# PIC32CM6408PL10028 device description
Architecture: CORTEX-M0PLUS; Family: PIC32CMPL; Series: PIC32CMPL10
Registers are 32-bit, read-write, reset 0x0 unless marked. A register's access mark holds for its fields unless they carry their own. Offsets are from the block's base; [hi:lo] are bit positions; {n}, {i} and the like mark numbered series; 'fields as' and 'values as' point back to an identical list; <NAME> marks a mode.

## RTC — Real-Time Counter
Instances: RTC 0x40002400
Modes: MODE0 when RTC.MODE0.CTRLA.MODE=0 (32-bit Counter Mode); MODE1 when RTC.MODE1.CTRLA.MODE=1 (16-bit Counter Mode); MODE2 when RTC.MODE2.CTRLA.MODE=2 (Clock and Calendar Mode with Alarm)
0x0E DBGCTRL 8-bit — Debug Control
  [0] DBGRUN — Debug Run
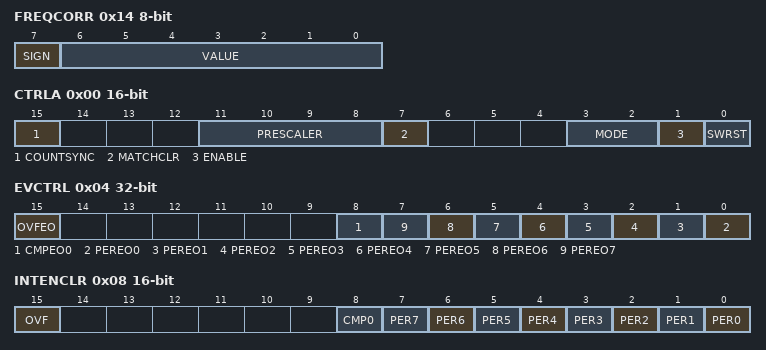
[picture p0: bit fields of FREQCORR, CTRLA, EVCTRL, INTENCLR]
0x14 FREQCORR 8-bit (WSYNC) — Frequency Correction
  [7] SIGN — Correction Sign
  [6:0] VALUE — Correction Value
0x00 CTRLA <MODE0> 16-bit (WSYNC) — MODE0 Control A
  [15] COUNTSYNC — COUNT Read Resynchronization Enable
  [11:8] PRESCALER
    0=OFF (CLK_RTC_CNT = GCLK_RTC/1); 1=DIV1 (CLK_RTC_CNT = GCLK_RTC/1); 2=DIV2 (CLK_RTC_CNT = GCLK_RTC/2); 3=DIV4 (CLK_RTC_CNT = GCLK_RTC/4); 4=DIV8 (CLK_RTC_CNT = GCLK_RTC/8); 5=DIV16 (CLK_RTC_CNT = GCLK_RTC/16); 6=DIV32 (CLK_RTC_CNT = GCLK_RTC/32); 7=DIV64 (CLK_RTC_CNT = GCLK_RTC/64); 8=DIV128 (CLK_RTC_CNT = GCLK_RTC/128); 9=DIV256 (CLK_RTC_CNT = GCLK_RTC/256); 10=DIV512 (CLK_RTC_CNT = GCLK_RTC/512); 11=DIV1024 (CLK_RTC_CNT = GCLK_RTC/1024)
  [7] MATCHCLR — Clear on Match
  [3:2] MODE — Operating Mode
    0=COUNT32 (Mode 0: 32-bit counter); 1=COUNT16 (Mode 1: 16-bit counter); 2=CLOCK (Mode 2: Clock/calendar)
  [1] ENABLE
  [0] SWRST — Software Reset
0x04 EVCTRL <MODE0> — MODE0 Event Control
  [15] OVFEO — Overflow Event Output Enable
  [8] CMPEO0 — Compare 0 Event Output Enable
  [n] PEREO{n} (n=0..7) — Periodic Interval {n} Event Output Enable
0x08 INTENCLR <MODE0> 16-bit (atomic clear) — MODE0 Interrupt Enable Clear
  [15] OVF — Overflow Interrupt Enable
  [8] CMP0 — Compare 0 Interrupt Enable
  [n] PER{n} (n=0..7) — Periodic Interval {n} Interrupt Enable
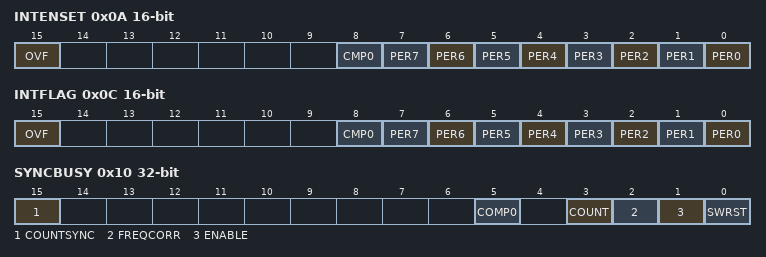
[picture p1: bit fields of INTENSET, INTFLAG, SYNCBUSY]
0x0A INTENSET <MODE0> 16-bit (atomic set) — MODE0 Interrupt Enable Set
  fields as INTENCLR<MODE0>
0x0C INTFLAG <MODE0> 16-bit (atomic clear) — MODE0 Interrupt Flag Status and Clear
  [15] OVF — Overflow
  [8] CMP0 — Compare 0
  [n] PER{n} (n=0..7) — Periodic Interval {n}
0x10 SYNCBUSY <MODE0> ro — MODE0 Synchronization Busy
  [15] COUNTSYNC — COUNT Read Resynchronization Enable Synchronization Busy
  [5] COMP0 — Compare 0 Value Synchronization Busy
  [3] COUNT — Counter Value Synchronization Busy
  [2] FREQCORR — Frequency Correction Synchronization Busy
  [1] ENABLE — Enable Synchronization Busy
  [0] SWRST — Software Reset Synchronization Busy
0x18 COUNT <MODE0> (WSYNC) — MODE0 Counter Value
  [31:0] COUNT — Counter Value
0x20 COMP <MODE0> (WSYNC) — MODE0 Compare # Value
  [31:0] COMP — Compare Value
0x00 CTRLA <MODE1> 16-bit (WSYNC) — MODE1 Control A
  [15] COUNTSYNC — COUNT Read Resynchronization Enable
  [11:8] PRESCALER
    values as CTRLA<MODE0>.PRESCALER
  [3:2] MODE — Operating Mode
    values as CTRLA<MODE0>.MODE
  [1] ENABLE
  [0] SWRST — Software Reset
0x04 EVCTRL <MODE1> — MODE1 Event Control
  [15] OVFEO — Overflow Event Output Enable
  [9] CMPEO1 — Compare 1 Event Output Enable
  [8] CMPEO0 — Compare 0 Event Output Enable
  [n] PEREO{n} (n=0..7) — Periodic Interval {n} Event Output Enable
0x08 INTENCLR <MODE1> 16-bit (atomic clear) — MODE1 Interrupt Enable Clear
  [15] OVF — Overflow Interrupt Enable
  [9] CMP1 — Compare 1 Interrupt Enable
  [8] CMP0 — Compare 0 Interrupt Enable
  [n] PER{n} (n=0..7) — Periodic Interval {n} Interrupt Enable
0x0A INTENSET <MODE1> 16-bit (atomic set) — MODE1 Interrupt Enable Set
  fields as INTENCLR<MODE1>
0x0C INTFLAG <MODE1> 16-bit (atomic clear) — MODE1 Interrupt Flag Status and Clear
  [15] OVF — Overflow
  [9] CMP1 — Compare 1
  [8] CMP0 — Compare 0
  [n] PER{n} (n=0..7) — Periodic Interval {n}
0x10 SYNCBUSY <MODE1> ro — MODE1 Synchronization Busy
  [15] COUNTSYNC — COUNT Read Resynchronization Enable Synchronization Busy
  [6] COMP1 — Compare 1 Value Synchronization Busy
  [5] COMP0 — Compare 0 Value Synchronization Busy
  [4] PER — Counter Period Synchronization Busy
  [3] COUNT — Counter Value Synchronization Busy
  [2] FREQCORR — Frequency Correction Synchronization Busy
  [1] ENABLE — Enable Synchronization Busy
  [0] SWRST — Software Reset Synchronization Busy
0x18 COUNT <MODE1> 16-bit (WSYNC) — MODE1 Counter Value
  [15:0] COUNT — Counter Value
0x1C PER <MODE1> 16-bit (WSYNC) — MODE1 Counter Period
  [15:0] PER — Counter Period
{0x20+2i} COMP[{i}] (i=0..1) <MODE1> 16-bit (WSYNC) — MODE1 Compare # Value
  [15:0] COMP — Compare Value
0x00 CTRLA <MODE2> 16-bit (WSYNC) — MODE2 Control A
  [15] CLOCKSYNC — CLOCK Read Resynchronization Enable
  [11:8] PRESCALER
    values as CTRLA<MODE0>.PRESCALER
  [7] MATCHCLR — Clear on Match
  [6] CLKREP — Clock Representation
    0=CLK24H (24 hour clock format); 1=CLK12H (12 hour (AM/PM) clock format)
  [3:2] MODE — Operating Mode
    values as CTRLA<MODE0>.MODE
  [1] ENABLE
  [0] SWRST — Software Reset
0x04 EVCTRL <MODE2> — MODE2 Event Control
  [15] OVFEO — Overflow Event Output Enable
  [8] ALARMEO0 — Alarm 0 Event Output Enable
  [n] PEREO{n} (n=0..7) — Periodic Interval {n} Event Output Enable
0x08 INTENCLR <MODE2> 16-bit (atomic clear) — MODE2 Interrupt Enable Clear
  [15] OVF — Overflow Interrupt Enable
  [8] ALARM0 — Alarm 0 Interrupt Enable
  [n] PER{n} (n=0..7) — Periodic Interval {n} Interrupt Enable
0x0A INTENSET <MODE2> 16-bit (atomic set) — MODE2 Interrupt Enable Set
  fields as INTENCLR<MODE2>
0x0C INTFLAG <MODE2> 16-bit (atomic clear) — MODE2 Interrupt Flag Status and Clear
  [15] OVF — Overflow
  [8] ALARM0
  [n] PER{n} (n=0..7) — Periodic Interval {n}
0x10 SYNCBUSY <MODE2> ro — MODE2 Synchronization Busy
  [15] CLOCKSYNC — CLOCK Read Resynchronization Enable Synchronization Busy
  [11] MASK0 — Alarm 0 Mask Synchronization Busy
  [5] ALARM0 — Alarm 0 Value Synchronization Busy
  [3] CLOCK — Clock Value Synchronization Busy
  [2] FREQCORR — Frequency Correction Synchronization Busy
  [1] ENABLE — Enable Synchronization Busy
  [0] SWRST — Software Reset Synchronization Busy
0x18 CLOCK <MODE2> (WSYNC) (modes: CLK12H when RTC.CTRLA.CLKREP=1; CLK24H when RTC.CTRLA.CLKREP=0) — MODE2 Clock Value
  [16] INDICATOR <CLK12H> — Meridiem Indicator
    0=AM (Before midday (AM)); 1=PM (After midday (PM))
  [15:12] HOUR <CLK12H>
  [16:12] HOUR <CLK24H>
  [31:26] YEAR <DEFAULT>
  [25:22] MONTH <DEFAULT>
    1=JAN (January); 2=FEB (February); 3=MAR (March); 4=APR (April); 5=MAY; 6=JUN (June); 7=JUL (July); 8=AUG (August); 9=SEP (September); 10=OCT (October); 11=NOV (November); 12=DEC (December)
  [21:17] DAY <DEFAULT>
  [11:6] MINUTE <DEFAULT>
  [5:0] SECOND <DEFAULT>
0x20 ALARM0 <MODE2> (WSYNC) (modes: CLK12H when RTC.CTRLA.CLKREP=1; CLK24H when RTC.CTRLA.CLKREP=0) — MODE2 Alarm 0 Value
  fields as CLOCK<MODE2>
0x24 MASK0 <MODE2> 8-bit (WSYNC) — MODE2 Alarm 0 Mask
  [2:0] SEL — Alarm Mask Selection
    0=OFF (Alarm Disabled); 1=SS (Match seconds only); 2=MMSS (Match seconds and minutes only); 3=HHMMSS (Match seconds, minutes, and hours only); 4=DDHHMMSS (Match seconds, minutes, hours, and days only); 5=MMDDHHMMSS (Match seconds, minutes, hours, days, and months only); 6=YYMMDDHHMMSS (Match seconds, minutes, hours, days, months, and years)
